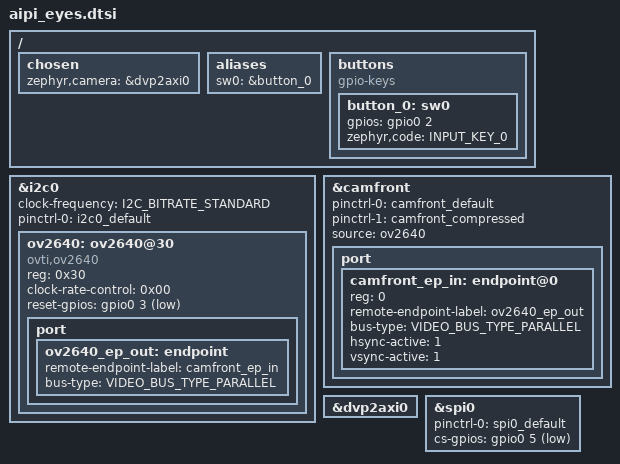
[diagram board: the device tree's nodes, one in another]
/*
 * Copyright (c) 2026 Panoramix Labs
 *
 * SPDX-License-Identifier: Apache-2.0
 */

#include <zephyr/dt-bindings/video/video-interfaces.h>

#include "ai_m61_32s.dtsi"
#include "aipi_eyes-pinctrl.dtsi"

/ {
	chosen {
		zephyr,camera = &dvp2axi0;
	};

	aliases {
		sw0 = &button_0;
	};

	buttons {
		compatible = "gpio-keys";

		/* BURN, the boot strap pin, shared with the backlight enable */
		button_0: sw0 {
			gpios = <&gpio0 2 GPIO_ACTIVE_HIGH>;
			zephyr,code = <INPUT_KEY_0>;
		};
	};
};

&i2c0 {
	status = "okay";
	clock-frequency = <I2C_BITRATE_STANDARD>;

	pinctrl-0 = <&i2c0_default>;
	pinctrl-names = "default";

	ov2640: ov2640@30 {
		compatible = "ovti,ov2640";
		reg = <0x30>;
		status = "okay";
		clock-rate-control = <0x00>;

		reset-gpios = <&gpio0 3 GPIO_ACTIVE_LOW>;

		port {
			ov2640_ep_out: endpoint {
				remote-endpoint-label = "camfront_ep_in";
				bus-type = <VIDEO_BUS_TYPE_PARALLEL>;
			};
		};
	};
};

&camfront {
	status = "okay";

	pinctrl-0 = <&camfront_default>;
	pinctrl-1 = <&camfront_compressed>;
	pinctrl-names = "default", "compressed";

	source = <&ov2640>;

	port {
		camfront_ep_in: endpoint@0 {
			reg = <0>;
			remote-endpoint-label = "ov2640_ep_out";
			bus-type = <VIDEO_BUS_TYPE_PARALLEL>;
			hsync-active = <1>;
			vsync-active = <1>;
		};
	};
};

&dvp2axi0 {
	status = "okay";
};

&spi0 {
	status = "okay";

	pinctrl-0 = <&spi0_default>;
	pinctrl-names = "default";

	/* shared between SD card and display, use only one */
	cs-gpios = <&gpio0 5 GPIO_ACTIVE_LOW>;
};
